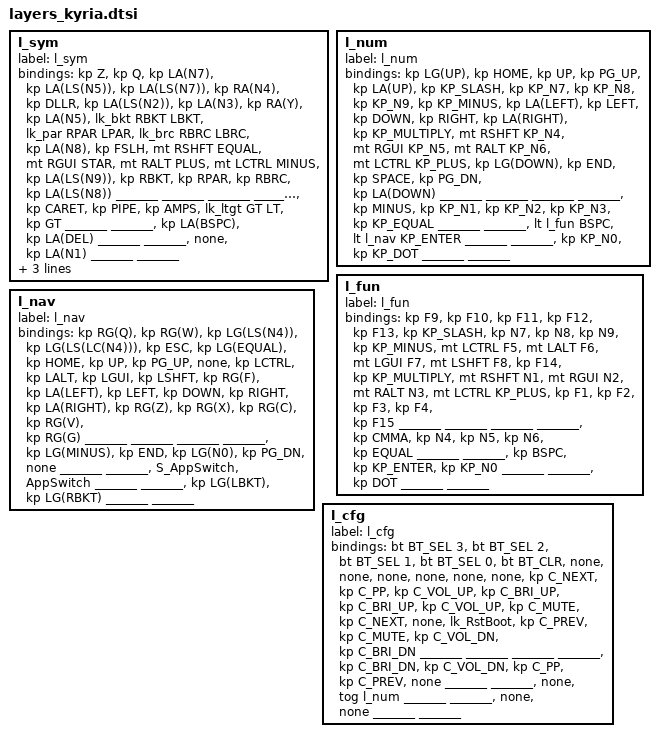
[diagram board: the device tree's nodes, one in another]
/*
 Building for a Kyria 50 key board
 */

/* The Kyria Keymap Key position names
 * ,-----------------------------------------------.                                  ,-----------------------------------------------.
 * |  LT5  |  LT4  |  LT3  |  LT2  |  LT1  |  LT0  |  LTA                        RTA  |  RT0  |  RT1  |  RT2  |  RT3  |  RT4  |  RT5  |
 * |-------+-------+-------+-------+-------+-------+                                  +-------+-------+-------+-------+-------+-------|
 * |  LM5  |  LM4  |  LM3  |  LM2  |  LM1  |  LM0  |  LMA                        RMA  |  RM0  |  RM1  |  RM2  |  RM3  |  RM4  |  RM5  |
 * |-------+-------+-------+-------+-------+-------+-------+-------.  ,-------+-------+-------+-------+-------+-------+-------+-------|
 * |  LB5  |  LB4  |  LB3  |  LB2  |  LB1  |  LB0  |  LF0  |  LF1  |  |  RF0  |  RF1  |  RB0  |  RB1  |  RB2  |  RB3  |  RB4  |  RB5  |
 * `-------+-------+-------+-------+-------+-------+-------+-------'  '-------+-------+-------+-------+-------+-------+-------+-------'
 *            LH5  |  LH4  |  LH3  |  LH2  |  LH1  |  LH0  |  LHA        RHA  |  RH0  |  RH1  |  RH2  |  RH3  |  RH4  |  RH5
 *                 `---------------------------------------'                  '---------------------------------------'
 */

//     ╭─────────────────────╮                  ╭─────────────────────╮
// LT5 │ LT4 LT3 LT2 LT1 LT0 │ LTA          RTB │ RT0 RT1 RT2 RT3 RT4 │ RT5
// LM5 │ LM4 LM3 LM2 LM1 LM0 | LMA          RMA | RT0 RM1 RM2 RM3 RM4 │ RM5
// LB5 │ LB4 LB3 LB2 LB1 LB0 │ LBA LBB  RBB RBA │ RB0 RB1 RB2 RB3 RB4 │ RB5
//     ╰───────────╮ LH2 LH1 │ LH0 LHA  RHA RH0 │ RH1 RH2 ╭───────────╯
//     LH5 LH4 LH3 ╰─────────╯                  ╰─────────╯ RH3 RH4 RH5


                        //                                       Symbol & math (for Mac)
                        //  * left paired symbols are "linger keys" via hold taps. Tap for left, hold for pair with insertion point between
                        //╭─────────────────────────────────────────────╮                ╭────────────────────────────────────────────╮
                        //|    Z   |    Q   |   ¶    |   †    |    ‡    |                |   ¢    |    $   |    €   |    £   |   ¥    |
                        //|    §   |    [   |   (    |   {    |    •    |                |   /    |    =   |    *   |    +   |   -    |
                        //|    ·   |    ]   |   )    |   }    |    °    |                |   ^    |    |   |    &   |    <   |   >    |
                        //╰─────────────────╮        | dwdlt  |  dwdr   |                | &none  |    ¡   |        ╭─────────────────╯
                        //                  ╰───────────────────────────╯                ╰──────────────────────────╯
                l_sym {
                    label = "l_sym";
                    bindings = <
&kp Z &kp Q &kp LA(N7) &kp LA(LS(N5)) &kp LA(LS(N7))                                                    &kp RA(N4)  &kp DLLR        &kp LA(LS(N2))  &kp LA(N3)      &kp RA(Y)
&kp LA(N5)  &lk_bkt RBKT LBKT &lk_par RPAR LPAR &lk_brc RBRC LBRC &kp LA(N8)                            &kp FSLH    &mt RSHFT EQUAL &mt RGUI STAR   &mt RALT PLUS   &mt LCTRL MINUS
&kp LA(LS(N9)) &kp RBKT &kp RPAR &kp RBRC   &kp LA(LS(N8)) _______  _______         _______     _______ &kp CARET   &kp PIPE        &kp AMPS        &lk_ltgt GT LT  &kp GT
               _______  _______  &kp LA(BSPC) &kp LA(DEL)  _______                              _______ &none       &kp LA(N1)      _______         _______
                    >;
            sensor-bindings = <&inc_dec_kp LG(MINUS) LG(EQUAL) &inc_dec_kp PG_UP PG_DN>;
                };

                        //                                        Nav & NumPad (standard)
                        //╭─────────────────────────────────────────────╮               ╭──────────────────────────────────────────╮
                        //|   Top  |  HOME  |   UP   |  PG_UP |   ¶up   |               |    /   |   7    |   8    |   9   |   -   |
                        //|  Lword |  LEFT  |  DOWN  |   RGT  |  Rword  |               |    *   |  S/4   |  G/5   |  A/6  |  C/+  |
                        //|   Bot  |   END  |   SPC  |  PG_DN |   ¶dn   |               |    -   |   1    |   2    |   3   |   =   |
                        //╰─────────────────╮        |  BSPC  |KP_ENTER |               |    0   |   .    |        ╭───────────────╯
                        //                  ╰───────────────────────────╯               ╰──────────────────────────╯
                l_num {
                        label = "l_num"; //
                        bindings = <

&kp LG(UP)    &kp HOME  &kp UP    &kp PG_UP  &kp LA(UP)                                                 &kp KP_SLASH    &kp KP_N7       &kp KP_N8       &kp KP_N9       &kp KP_MINUS
&kp LA(LEFT)  &kp LEFT  &kp DOWN  &kp RIGHT  &kp LA(RIGHT)                                              &kp KP_MULTIPLY &mt RSHFT KP_N4 &mt RGUI KP_N5  &mt RALT KP_N6  &mt LCTRL KP_PLUS
&kp LG(DOWN)  &kp END   &kp SPACE &kp PG_DN  &kp LA(DOWN) _______  _______          _______     _______ &kp MINUS       &kp KP_N1       &kp KP_N2       &kp KP_N3       &kp KP_EQUAL
              _______   _______ &lt l_fun BSPC &lt l_nav KP_ENTER _______                       _______ &kp KP_N0       &kp KP_DOT      _______         _______
                        >;
                };

/* L_FUN LAYER K-key row (left) and Num row (right)
         ╭──────────────────────────────────────────╮               ╭──────────────────────────────────────────╮
 RGB_TOG │ F13      F7      F8      F9      F10     │               │ /       7       8       9       -        │ RGB_MOD
 RGB_VAI │ C_T(F14) A_T(F1) G_T(F2) S_T(F3) F11     |               | *       S_T(1)  G_T(2)  A_T(3)  C_T(+)   │ RGB_HUI
 RGB_VAD │ F15      F4      F5      F6      F12     │ __ __   __ __ │ ,       4       5       6       =        │ RGB_HUD
         ╰────────────────╮ __      __      INS     │ __         __ │ 0       .       TG(LN)  ╭────────────────╯
              __      __  ╰─────────────────────────╯               ╰─────────────────────────╯ __       __
*/
                l_fun {
                        label = "l_fun";
                        bindings = <

&kp F9       &kp F10    &kp F11     &kp F12     &kp F13                                             &kp KP_SLASH    &kp N7          &kp N8          &kp N9      &kp KP_MINUS
&mt LCTRL F5 &mt LALT F6 &mt LGUI F7 &mt LSHFT F8 &kp F14                                           &kp KP_MULTIPLY &mt RSHFT N1    &mt RGUI N2     &mt RALT N3 &mt LCTRL KP_PLUS
&kp F1       &kp F2     &kp F3      &kp F4      &kp F15 _______  _______            _______ _______ &kp CMMA        &kp N4          &kp N5          &kp N6      &kp EQUAL
             _______    _______     &kp BSPC    &kp KP_ENTER &kp KP_N0                      _______ _______         &kp DOT         _______         _______
                        >;
                };

                        //                                           shorcuts & Navigation
                        //╭─────────────────────────────────────────────╮                ╭────────────────────────────────────────────╮
                        //|  close |   quit  | ScrCp | SelCp |  pstmtch |                |   Top   |  HOME  |   UP   |  PG_UP | ¶up   |
                        //|  ctrl  |   alt   |  gui  |  shft |   Find   |                |  Lword  |  LEFT  |  DOWN  |   RGT  | Rword |
                        //|  undo  |   cut   |  copy |  pste |  findAgn |                |   Botm  |   END  |  DOWN  |  PG_DN | ¶dn   |
                        //╰──────────────────╮       | APPSW |   APPSW  |                |  back   |  fwd   |        ╭────────────────╯
                        //                   ╰──────────────────────────╯                ╰───────────────────────────╯
                l_nav {
                    label = "l_nav";
                    bindings = <
&kp RG(Q)   &kp RG(W)   &kp LG(LS(N4))  &kp LG(LS(LC(N4))) &kp ESC                                  &kp LG(EQUAL)   &kp HOME        &kp UP          &kp PG_UP   &none
&kp LCTRL   &kp LALT    &kp LGUI        &kp LSHFT   &kp RG(F)                                       &kp LA(LEFT)    &kp LEFT        &kp DOWN        &kp RIGHT   &kp LA(RIGHT)
&kp RG(Z)   &kp RG(X)   &kp RG(C)       &kp RG(V)   &kp RG(G) _______  _______      _______ _______ &kp LG(MINUS)   &kp END         &kp LG(N0)      &kp PG_DN   &none
            _______     _______        &S_AppSwitch &AppSwitch _______                      _______ &kp LG(LBKT)    &kp LG(RBKT)    _______         _______
                    >;
                };

                        //                                     Keyboard & System Settings
                        //   L_CFG Keyboard Configuration (left) and Media Settings (right)
                        //╭───────────────────────────────────────────────╮                ╭────────────────────────────────────────────────╮
                        //│  BT3     BT2     BT1     BT0        BT_Clr    │                │ SK_ZOOMRST KC_NUM  KC_EJCT KC_NO   (C(A(del))) │
                        //│  HD_AKTg L_0     L_1     KC_VOLU    KC_BRIU   |                | SK_ZOOMOUT KC_MPRV KC_MUTE KC_MNXT KC_NO       │
                        //│  QK_BOOT AG_SWAP AG_NORM KC_VOLD    KC_BRID   │                │ SK_ZOOMIN  KC_MRWD KC_MPLY KC_MFFD KILL        │
                        //╰──────────────────╮       SK_ZOOMOUT SK_ZOOMIN │                │ SK_ZOOMIN  SK_ZOOMOUT      ╭───────────────────╯
                        //                   ╰────────────────────────────╯                ╰────────────────────────────╯
                l_cfg {
                        label = "l_cfg";
                        bindings = <
//&none &none &none &none &none &none &none &none &none &none &none &none
&bt BT_SEL 3 &bt BT_SEL 2 &bt BT_SEL 1 &bt BT_SEL 0 &bt BT_CLR                                      &none           &none           &none           &none       &none
&none       &kp C_NEXT  &kp C_PP    &kp C_VOL_UP &kp C_BRI_UP                                       &kp C_BRI_UP    &kp C_VOL_UP    &kp C_MUTE      &kp C_NEXT  &none
&lk_RstBoot &kp C_PREV  &kp C_MUTE  &kp C_VOL_DN &kp C_BRI_DN _______  _______      _______ _______ &kp C_BRI_DN    &kp C_VOL_DN    &kp C_PP        &kp C_PREV  &none
            _______     _______     &none       &tog l_num    _______                       _______ &none           &none           _______         _______
                        >;
                };
